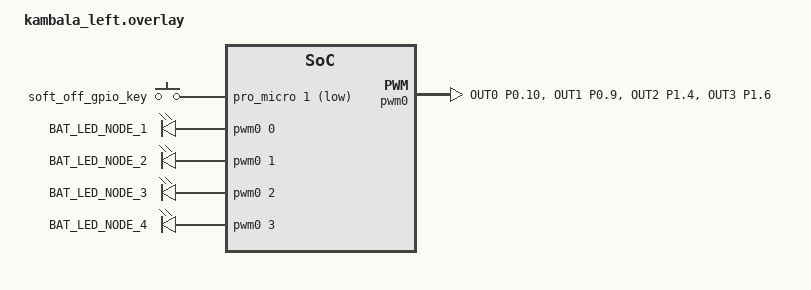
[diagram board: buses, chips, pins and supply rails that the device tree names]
/*
 * Copyright (c) 2020 Pete Johanson
 *
 * SPDX-License-Identifier: MIT
 */

#include "kambala.dtsi"

&kscan0 {
    col-gpios
        = <&pro_micro 21 GPIO_ACTIVE_HIGH>
        , <&pro_micro 20 GPIO_ACTIVE_HIGH>
        , <&pro_micro 19 GPIO_ACTIVE_HIGH>
        , <&pro_micro 18 GPIO_ACTIVE_HIGH>
        , <&pro_micro 15 GPIO_ACTIVE_HIGH>
        , <&pro_micro 14 GPIO_ACTIVE_HIGH>
        ;
};
/ {
    behaviors {
        hw_soft_off: hw_soft_off {
            compatible = "zmk,behavior-soft-off";
            #binding-cells = <0>;
            split-peripheral-off-on-press; // Turn peripheral off immediately for reliability
            hold-time-ms = <1000>; // Only turn off if the key is held for 2 seconds or longer.
        };
    };
    keys {
        compatible = "gpio-keys";
        soft_off_gpio_key: soft_off_gpio_key {
            gpios = <&pro_micro 1 (GPIO_ACTIVE_LOW | GPIO_PULL_UP) >;
        };
    };
    wakeup_scan: wakeup_scan {
        compatible = "zmk,kscan-gpio-direct";
        input-keys = <&soft_off_gpio_key>;
        wakeup-source;
    };
};

/ {
    backlight: pwmleds {
        compatible = "pwm-leds";
        pwm_led_0: led_0 {
            pwms = <&pwm0 0 PWM_MSEC(10) PWM_POLARITY_NORMAL>;
            label = "BAT_LED_NODE_1";
        };
        pwm_led_1: led_1 {
            pwms = <&pwm0 1 PWM_MSEC(10) PWM_POLARITY_NORMAL>;
            label = "BAT_LED_NODE_2";
        };
        pwm_led_2: led_2 {
            label = "BAT_LED_NODE_3";
            pwms = <&pwm0 2 PWM_MSEC(10) PWM_POLARITY_NORMAL>;
        };
        pwm_led_3: led_3 {
            label = "BAT_LED_NODE_4";
            pwms = <&pwm0 3 PWM_MSEC(10) PWM_POLARITY_NORMAL>;
        };
    };
};

&pwm0 {
    status = "okay";
    pinctrl-0 = <&pwm0_default>;
    pinctrl-1 = <&pwm0_sleep>;
    pinctrl-names = "default", "sleep";
};

&pinctrl {
    // Other Pinctrl definitions go here
    pwm0_default: pwm0_default {
        group1 {
            psels = <NRF_PSEL(PWM_OUT0, 0, 10)>,  // LED 0 P0.10 (pin 16)
                    <NRF_PSEL(PWM_OUT1, 0, 9)>,   // LED 1 P0.09 (pin 10)
                    <NRF_PSEL(PWM_OUT2, 1, 4)>,   // LED 2 P1.04 (pin 8)
                    <NRF_PSEL(PWM_OUT3, 1, 6)>;   // LED 3 P1.06 (pin 9)
        };
    };
    pwm0_sleep: pwm0_sleep {
        group1 {
            psels = <NRF_PSEL(PWM_OUT0, 0, 10)>,  // LED 0 P0.10 (pin 16)
                    <NRF_PSEL(PWM_OUT1, 0, 9)>,   // LED 1 P0.09 (pin 10)
                    <NRF_PSEL(PWM_OUT2, 1, 4)>,   // LED 2 P1.04 (pin 8)
                    <NRF_PSEL(PWM_OUT3, 1, 6)>;   // LED 3 P1.06 (pin 9)

            low-power-enable;
        };
    };
};

